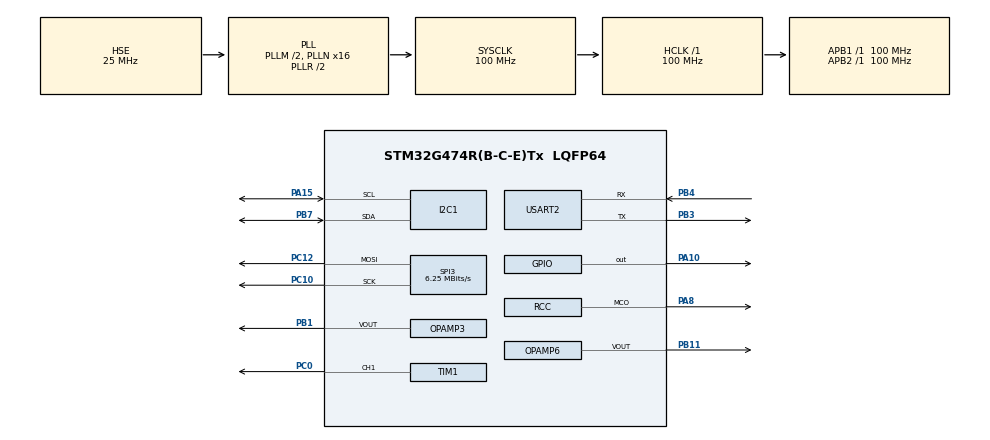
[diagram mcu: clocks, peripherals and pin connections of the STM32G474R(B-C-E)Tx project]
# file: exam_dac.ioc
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CRC.CRCLength=CRC_POLYLENGTH_16B
CRC.DefaultInitValueUse=DEFAULT_INIT_VALUE_DISABLE
CRC.DefaultPolynomialUse=DEFAULT_POLYNOMIAL_DISABLE
CRC.GeneratingPolynomial=X12+X5+X0
DAC3.DAC_Channel-DAC_OUT2_Int=DAC_CHANNEL_2
DAC3.DAC_DMADoubleDataMode-DAC_OUT1_Int=ENABLE
DAC3.DAC_DMADoubleDataMode-DAC_OUT2_Int=ENABLE
DAC3.DAC_Trigger_OUT1-DAC_OUT1_Int=DAC_TRIGGER_T15_TRGO
DAC3.DAC_Trigger_OUT2-DAC_OUT2_Int=DAC_TRIGGER_T15_TRGO
Dma.DAC3_CH1.1.Direction=DMA_MEMORY_TO_PERIPH
Dma.DAC3_CH1.1.EventEnable=DISABLE
Dma.DAC3_CH1.1.Instance=DMA1_Channel1
Dma.DAC3_CH1.1.MemDataAlignment=DMA_MDATAALIGN_WORD
Dma.DAC3_CH1.1.MemInc=DMA_MINC_ENABLE
Dma.DAC3_CH1.1.Mode=DMA_CIRCULAR
Dma.DAC3_CH1.1.PeriphDataAlignment=DMA_PDATAALIGN_WORD
Dma.DAC3_CH1.1.PeriphInc=DMA_PINC_DISABLE
Dma.DAC3_CH1.1.Polarity=HAL_DMAMUX_REQ_GEN_RISING
Dma.DAC3_CH1.1.Priority=DMA_PRIORITY_LOW
Dma.DAC3_CH1.1.RequestNumber=1
Dma.DAC3_CH1.1.SignalID=NONE
Dma.DAC3_CH1.1.SyncEnable=DISABLE
Dma.DAC3_CH1.1.SyncPolarity=HAL_DMAMUX_SYNC_NO_EVENT
Dma.DAC3_CH1.1.SyncRequestNumber=1
Dma.DAC3_CH1.1.SyncSignalID=NONE
Dma.DAC3_CH2.2.Direction=DMA_MEMORY_TO_PERIPH
Dma.DAC3_CH2.2.EventEnable=DISABLE
Dma.DAC3_CH2.2.Instance=DMA1_Channel2
Dma.DAC3_CH2.2.MemDataAlignment=DMA_MDATAALIGN_WORD
Dma.DAC3_CH2.2.MemInc=DMA_MINC_ENABLE
Dma.DAC3_CH2.2.Mode=DMA_CIRCULAR
Dma.DAC3_CH2.2.PeriphDataAlignment=DMA_PDATAALIGN_WORD
Dma.DAC3_CH2.2.PeriphInc=DMA_PINC_DISABLE
Dma.DAC3_CH2.2.Polarity=HAL_DMAMUX_REQ_GEN_RISING
Dma.DAC3_CH2.2.Priority=DMA_PRIORITY_LOW
Dma.DAC3_CH2.2.RequestNumber=1
Dma.DAC3_CH2.2.SignalID=NONE
Dma.DAC3_CH2.2.SyncEnable=DISABLE
Dma.DAC3_CH2.2.SyncPolarity=HAL_DMAMUX_SYNC_NO_EVENT
Dma.DAC3_CH2.2.SyncRequestNumber=1
Dma.DAC3_CH2.2.SyncSignalID=NONE
Dma.Request0=USART2_RX
Dma.Request1=DAC3_CH1
Dma.Request2=DAC3_CH2
Dma.USART2_RX.0.Direction=DMA_PERIPH_TO_MEMORY
Dma.USART2_RX.0.EventEnable=DISABLE
Dma.USART2_RX.0.Instance=DMA2_Channel8
Dma.USART2_RX.0.MemDataAlignment=DMA_MDATAALIGN_BYTE
Dma.USART2_RX.0.MemInc=DMA_MINC_ENABLE
Dma.USART2_RX.0.Mode=DMA_NORMAL
Dma.USART2_RX.0.PeriphDataAlignment=DMA_PDATAALIGN_BYTE
Dma.USART2_RX.0.PeriphInc=DMA_PINC_DISABLE
Dma.USART2_RX.0.Polarity=HAL_DMAMUX_REQ_GEN_RISING
Dma.USART2_RX.0.Priority=DMA_PRIORITY_LOW
Dma.USART2_RX.0.RequestNumber=1
Dma.USART2_RX.0.SignalID=NONE
Dma.USART2_RX.0.SyncEnable=DISABLE
Dma.USART2_RX.0.SyncPolarity=HAL_DMAMUX_SYNC_NO_EVENT
Dma.USART2_RX.0.SyncRequestNumber=1
Dma.USART2_RX.0.SyncSignalID=NONE
I2C1.Timing=0x20B182BE
Mcu.Family=STM32G4
Mcu.Name=STM32G474R(B-C-E)Tx
Mcu.Package=LQFP64
NVIC.DMA2_Channel8_IRQn=true\:0\:0\:false\:false\:true\:false\:true\:true
NVIC.PriorityGroup=NVIC_PRIORITYGROUP_4
NVIC.USART2_IRQn=true\:0\:0\:false\:false\:true\:true\:true\:true
OPAMP3.PowerMode=OPAMP_POWERMODE_HIGHSPEED
OPAMP6.PowerMode=OPAMP_POWERMODE_HIGHSPEED
PA10.GPIO_Speed=GPIO_SPEED_FREQ_VERY_HIGH
PA10.PinState=GPIO_PIN_SET
PA10.Signal=GPIO_Output
PA13.Mode=Serial_Wire
PA13.Signal=SYS_JTMS-SWDIO
PA14.Mode=Serial_Wire
PA14.Signal=SYS_JTCK-SWCLK
PA15.Mode=I2C
PA15.Signal=I2C1_SCL
PA8.GPIO_Speed=GPIO_SPEED_FREQ_MEDIUM
PA8.Mode=Clock-out
PA8.Signal=RCC_MCO
PB1.Mode=Follower-DAC_OUT2-INP
PB1.Signal=OPAMP3_VOUT
PB11.Mode=Follower-DAC_OUT2-INP
PB11.Signal=OPAMP6_VOUT
PB3.Mode=Asynchronous
PB3.Signal=USART2_TX
PB4.Mode=Asynchronous
PB4.Signal=USART2_RX
PB7.Mode=I2C
PB7.Signal=I2C1_SDA
PC0.Signal=S_TIM1_CH1
PC10.Mode=TX_Only_Simplex_Unidirect_Master
PC10.Signal=SPI3_SCK
PC12.Mode=TX_Only_Simplex_Unidirect_Master
PC12.Signal=SPI3_MOSI
PF0-OSC_IN.Mode=HSE-External-Oscillator
PF0-OSC_IN.Signal=RCC_OSC_IN
PF1-OSC_OUT.Mode=HSE-External-Oscillator
PF1-OSC_OUT.Signal=RCC_OSC_OUT
ProjectManager.HeapSize=0x200
ProjectManager.StackSize=0x400
ProjectManager.TargetToolchain=STM32CubeIDE
RCC.ADC12Freq_Value=100000000
RCC.ADC345Freq_Value=100000000
RCC.AHBFreq_Value=100000000
RCC.APB1Freq_Value=100000000
RCC.APB1TimFreq_Value=100000000
RCC.APB2Freq_Value=100000000
RCC.APB2TimFreq_Value=100000000
RCC.CortexFreq_Value=100000000
RCC.EXTERNAL_CLOCK_VALUE=12288000
RCC.HCLKFreq_Value=100000000
RCC.HSE_VALUE=25000000
RCC.HSI48_VALUE=48000000
RCC.HSI_VALUE=16000000
RCC.LSE_VALUE=32768
RCC.PLLM=RCC_PLLM_DIV2
RCC.PLLN=16
RCC.PLLSourceVirtual=RCC_PLLSOURCE_HSE
RCC.RCC_MCO1Source=RCC_MCO1SOURCE_HSE
RCC.SYSCLKFreq_VALUE=100000000
RCC.SYSCLKSource=RCC_SYSCLKSOURCE_PLLCLK
RCC.USART2CLockSelection=RCC_USART2CLKSOURCE_SYSCLK
RCC.USBFreq_Value=100000000
RCC.VCOOutputFreq_Value=200000000
SH.S_TIM1_CH1.0=TIM1_CH1,PWM Generation1 CH1
SPI3.BaudRatePrescaler=SPI_BAUDRATEPRESCALER_16
SPI3.CLKPolarity=SPI_POLARITY_HIGH
SPI3.CalculateBaudRate=6.25 MBits/s
SPI3.DataSize=SPI_DATASIZE_16BIT
SPI3.Direction=SPI_DIRECTION_2LINES
SPI3.Mode=SPI_MODE_MASTER
SPI3.VirtualType=VM_MASTER
TIM1.Channel-PWM\ Generation1\ CH1=TIM_CHANNEL_1
TIM1.PeriodNoDither=24
TIM15.AutoReloadPreload=TIM_AUTORELOAD_PRELOAD_DISABLE
TIM15.Dithering=Disable
TIM15.Integer_PeriodDither=4
TIM15.PeriodNoDither=4
TIM15.RepetitionCounter=0
TIM15.TIM_MasterOutputTrigger=TIM_TRGO_UPDATE
USART2.VirtualMode-Asynchronous=VM_ASYNC
VP_CORDIC_VS_CORDIC.Mode=CORDIC_Activate
VP_CRC_VS_CRC.Mode=CRC_Activate
VP_DAC3_VS_DACI1.Mode=DAC_OUT1_Int
VP_DAC3_VS_DACI2.Mode=DAC_OUT2_Int
VP_SYS_VS_DBSignals.Mode=DisableDeadBatterySignals
VP_TIM15_VS_ClockSourceINT.Mode=Internal
VP_TIM1_VS_ClockSourceINT.Mode=Internal
board=custom

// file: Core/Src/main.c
/* USER CODE BEGIN Header */
/**
  ******************************************************************************
  * @file           : main.c
  * @brief          : Main program body
  ******************************************************************************
  * @attention
  *
  * Copyright (c) 2024 STMicroelectronics.
  * All rights reserved.
  *
  * This software is licensed under terms that can be found in the LICENSE file
  * in the root directory of this software component.
  * If no LICENSE file comes with this software, it is provided AS-IS.
  *
  ******************************************************************************
  */
/* USER CODE END Header */
#include "main.h"

/* USER CODE BEGIN Includes */
#include "dds.h"
#include <math.h>
#include <stm32g4xx_hal_cordic.h>
/* USER CODE END Includes */

CORDIC_HandleTypeDef hcordic;

CRC_HandleTypeDef hcrc;

DAC_HandleTypeDef hdac3;
DMA_HandleTypeDef hdma_dac3_ch1;
DMA_HandleTypeDef hdma_dac3_ch2;

I2C_HandleTypeDef hi2c1;

OPAMP_HandleTypeDef hopamp3;
OPAMP_HandleTypeDef hopamp6;

SPI_HandleTypeDef hspi3;

TIM_HandleTypeDef htim1;
TIM_HandleTypeDef htim15;

UART_HandleTypeDef huart2;
DMA_HandleTypeDef hdma_usart2_rx;

/* USER CODE BEGIN PV */
uint16_t sin_data[10]={621,730,797,797,730,621,511,444,444,511};
/* USER CODE END PV */

void SystemClock_Config(void);
static void MX_GPIO_Init(void);
static void MX_DMA_Init(void);
static void MX_CRC_Init(void);
static void MX_USART2_UART_Init(void);
static void MX_TIM1_Init(void);
static void MX_I2C1_Init(void);
static void MX_SPI3_Init(void);
static void MX_DAC3_Init(void);
static void MX_TIM15_Init(void);
static void MX_CORDIC_Init(void);
static void MX_OPAMP6_Init(void);
static void MX_OPAMP3_Init(void);
/* USER CODE BEGIN PFP */

#define length 10
void set_dac(uint16_t offset)
{

//	  uint32_t temp1[length];
//	  uint32_t temp2[length];
//	  uint16_t hsdac_buffer[length];
//	  for (int i = 0; i < length; ++i)
//	  {
//		  temp1[i] = (1llu<<32) / length * i;
//	  }
//
//	  HAL_CORDIC_CalculateZO(&hcordic, temp1, temp2, length,10);
//	  for (int i= 0 ; i < length; ++i)
//	  {
//		  hsdac_buffer[i] = (temp2[i] + (1<< 31))>>21;
//		  hsdac_buffer[i] += offset;
//	  }
	  HAL_DAC_Start_DMA(&hdac3, DAC1_CHANNEL_1, sin_data, length / 2, DAC_ALIGN_12B_R);
	  //HAL_DAC_Start_DMA(&hdac3, DAC1_CHANNEL_2, sin_data, length / 2, DAC_ALIGN_12B_R);
//	  uint16_t dither[1000];
//	  int time_dither = 4;
//	  float e = 0;
//	  for (int i = 0 ; i < 1000 ; ++i)
//	  {
//
//		  e /= 2;
//		  if (e <1.14 )
//		  {
//
//			  dither[i] = 2;
//			  e +=2 ;
//		  }
//		  else
//		  {
//			  dither[i] = 1;
//			  e += 1;
//		  }
//	  }
//	  uint16_t dither[10] = {4,4,4,4,5,4,4,4,4,5};
//	  HAL_TIM_Base_Start_DMA(&htim15 ,dither , 1000 );
//	  (&htim15)->Instance->ARR = (uint32_t)(4);
//	  HAL_TIM_PWM_Start(&htim15, TIM_CHANNEL_1);
	  (&htim15)->Instance->ARR = (uint32_t)(4);
	  HAL_OPAMP_Start(&hopamp6);
	 // HAL_OPAMP_Start(&hopamp3);
	  HAL_TIM_Base_Start(&htim15);

}
/* USER CODE END PFP */

int main(void)
{

  /* MCU Configuration--------------------------------------------------------*/

  /* Reset of all peripherals, Initializes the Flash interface and the Systick. */
  HAL_Init();

  /* Configure the system clock */
  SystemClock_Config();

  /* Initialize all configured peripherals */
  MX_GPIO_Init();
  MX_DMA_Init();
  MX_CRC_Init();
  MX_USART2_UART_Init();
  MX_TIM1_Init();
  MX_I2C1_Init();
  MX_SPI3_Init();
  MX_DAC3_Init();
  MX_TIM15_Init();
  MX_CORDIC_Init();
  MX_OPAMP6_Init();
  MX_OPAMP3_Init();
  /* USER CODE BEGIN 2 */
  set_dac(1241);
  /* USER CODE END 2 */

  /* Infinite loop */
  while (1)
  {

  }
}

void SystemClock_Config(void)
{
  RCC_OscInitTypeDef RCC_OscInitStruct = {0};
  RCC_ClkInitTypeDef RCC_ClkInitStruct = {0};

  /** Configure the main internal regulator output voltage
  */
  HAL_PWREx_ControlVoltageScaling(PWR_REGULATOR_VOLTAGE_SCALE1);

  /** Initializes the RCC Oscillators according to the specified parameters
  * in the RCC_OscInitTypeDef structure.
  */
  RCC_OscInitStruct.OscillatorType = RCC_OSCILLATORTYPE_HSE;
  RCC_OscInitStruct.HSEState = RCC_HSE_ON;
  RCC_OscInitStruct.PLL.PLLState = RCC_PLL_ON;
  RCC_OscInitStruct.PLL.PLLSource = RCC_PLLSOURCE_HSE;
  RCC_OscInitStruct.PLL.PLLM = RCC_PLLM_DIV2;
  RCC_OscInitStruct.PLL.PLLN = 16;
  RCC_OscInitStruct.PLL.PLLP = RCC_PLLP_DIV2;
  RCC_OscInitStruct.PLL.PLLQ = RCC_PLLQ_DIV2;
  RCC_OscInitStruct.PLL.PLLR = RCC_PLLR_DIV2;
  if (HAL_RCC_OscConfig(&RCC_OscInitStruct) != HAL_OK)
  {
    Error_Handler();
  }

  /** Initializes the CPU, AHB and APB buses clocks
  */
  RCC_ClkInitStruct.ClockType = RCC_CLOCKTYPE_HCLK|RCC_CLOCKTYPE_SYSCLK
                              |RCC_CLOCKTYPE_PCLK1|RCC_CLOCKTYPE_PCLK2;
  RCC_ClkInitStruct.SYSCLKSource = RCC_SYSCLKSOURCE_PLLCLK;
  RCC_ClkInitStruct.AHBCLKDivider = RCC_SYSCLK_DIV1;
  RCC_ClkInitStruct.APB1CLKDivider = RCC_HCLK_DIV1;
  RCC_ClkInitStruct.APB2CLKDivider = RCC_HCLK_DIV1;

  if (HAL_RCC_ClockConfig(&RCC_ClkInitStruct, FLASH_LATENCY_3) != HAL_OK)
  {
    Error_Handler();
  }
  HAL_RCC_MCOConfig(RCC_MCO1, RCC_MCO1SOURCE_HSE, RCC_MCODIV_1);
}

static void MX_CORDIC_Init(void)
{

  hcordic.Instance = CORDIC;
  if (HAL_CORDIC_Init(&hcordic) != HAL_OK)
  {
    Error_Handler();
  }

}

static void MX_CRC_Init(void)
{

  hcrc.Instance = CRC;
  hcrc.Init.DefaultPolynomialUse = DEFAULT_POLYNOMIAL_DISABLE;
  hcrc.Init.DefaultInitValueUse = DEFAULT_INIT_VALUE_DISABLE;
  hcrc.Init.GeneratingPolynomial = 4129;
  hcrc.Init.CRCLength = CRC_POLYLENGTH_16B;
  hcrc.Init.InitValue = 0;
  hcrc.Init.InputDataInversionMode = CRC_INPUTDATA_INVERSION_NONE;
  hcrc.Init.OutputDataInversionMode = CRC_OUTPUTDATA_INVERSION_DISABLE;
  hcrc.InputDataFormat = CRC_INPUTDATA_FORMAT_BYTES;
  if (HAL_CRC_Init(&hcrc) != HAL_OK)
  {
    Error_Handler();
  }

}

static void MX_DAC3_Init(void)
{

  DAC_ChannelConfTypeDef sConfig = {0};

  /** DAC Initialization
  */
  hdac3.Instance = DAC3;
  if (HAL_DAC_Init(&hdac3) != HAL_OK)
  {
    Error_Handler();
  }

  /** DAC channel OUT1 config
  */
  sConfig.DAC_HighFrequency = DAC_HIGH_FREQUENCY_INTERFACE_MODE_AUTOMATIC;
  sConfig.DAC_DMADoubleDataMode = ENABLE;
  sConfig.DAC_SignedFormat = DISABLE;
  sConfig.DAC_SampleAndHold = DAC_SAMPLEANDHOLD_DISABLE;
  sConfig.DAC_Trigger = DAC_TRIGGER_T15_TRGO;
  sConfig.DAC_Trigger2 = DAC_TRIGGER_NONE;
  sConfig.DAC_OutputBuffer = DAC_OUTPUTBUFFER_DISABLE;
  sConfig.DAC_ConnectOnChipPeripheral = DAC_CHIPCONNECT_INTERNAL;
  sConfig.DAC_UserTrimming = DAC_TRIMMING_FACTORY;
  if (HAL_DAC_ConfigChannel(&hdac3, &sConfig, DAC_CHANNEL_1) != HAL_OK)
  {
    Error_Handler();
  }

  /** DAC channel OUT2 config
  */
  if (HAL_DAC_ConfigChannel(&hdac3, &sConfig, DAC_CHANNEL_2) != HAL_OK)
  {
    Error_Handler();
  }

}

static void MX_I2C1_Init(void)
{

  hi2c1.Instance = I2C1;
  hi2c1.Init.Timing = 0x20B182BE;
  hi2c1.Init.OwnAddress1 = 0;
  hi2c1.Init.AddressingMode = I2C_ADDRESSINGMODE_7BIT;
  hi2c1.Init.DualAddressMode = I2C_DUALADDRESS_DISABLE;
  hi2c1.Init.OwnAddress2 = 0;
  hi2c1.Init.OwnAddress2Masks = I2C_OA2_NOMASK;
  hi2c1.Init.GeneralCallMode = I2C_GENERALCALL_DISABLE;
  hi2c1.Init.NoStretchMode = I2C_NOSTRETCH_DISABLE;
  if (HAL_I2C_Init(&hi2c1) != HAL_OK)
  {
    Error_Handler();
  }

  /** Configure Analogue filter
  */
  if (HAL_I2CEx_ConfigAnalogFilter(&hi2c1, I2C_ANALOGFILTER_ENABLE) != HAL_OK)
  {
    Error_Handler();
  }

  /** Configure Digital filter
  */
  if (HAL_I2CEx_ConfigDigitalFilter(&hi2c1, 0) != HAL_OK)
  {
    Error_Handler();
  }

}

static void MX_OPAMP3_Init(void)
{

  hopamp3.Instance = OPAMP3;
  hopamp3.Init.PowerMode = OPAMP_POWERMODE_HIGHSPEED;
  hopamp3.Init.Mode = OPAMP_FOLLOWER_MODE;
  hopamp3.Init.NonInvertingInput = OPAMP_NONINVERTINGINPUT_DAC;
  hopamp3.Init.InternalOutput = DISABLE;
  hopamp3.Init.TimerControlledMuxmode = OPAMP_TIMERCONTROLLEDMUXMODE_DISABLE;
  hopamp3.Init.UserTrimming = OPAMP_TRIMMING_FACTORY;
  if (HAL_OPAMP_Init(&hopamp3) != HAL_OK)
  {
    Error_Handler();
  }

}

static void MX_OPAMP6_Init(void)
{

  hopamp6.Instance = OPAMP6;
  hopamp6.Init.PowerMode = OPAMP_POWERMODE_HIGHSPEED;
  hopamp6.Init.Mode = OPAMP_FOLLOWER_MODE;
  hopamp6.Init.NonInvertingInput = OPAMP_NONINVERTINGINPUT_DAC;
  hopamp6.Init.InternalOutput = DISABLE;
  hopamp6.Init.TimerControlledMuxmode = OPAMP_TIMERCONTROLLEDMUXMODE_DISABLE;
  hopamp6.Init.UserTrimming = OPAMP_TRIMMING_FACTORY;
  if (HAL_OPAMP_Init(&hopamp6) != HAL_OK)
  {
    Error_Handler();
  }

}

static void MX_SPI3_Init(void)
{

  /* SPI3 parameter configuration*/
  hspi3.Instance = SPI3;
  hspi3.Init.Mode = SPI_MODE_MASTER;
  hspi3.Init.Direction = SPI_DIRECTION_2LINES;
  hspi3.Init.DataSize = SPI_DATASIZE_16BIT;
  hspi3.Init.CLKPolarity = SPI_POLARITY_HIGH;
  hspi3.Init.CLKPhase = SPI_PHASE_1EDGE;
  hspi3.Init.NSS = SPI_NSS_SOFT;
  hspi3.Init.BaudRatePrescaler = SPI_BAUDRATEPRESCALER_16;
  hspi3.Init.FirstBit = SPI_FIRSTBIT_MSB;
  hspi3.Init.TIMode = SPI_TIMODE_DISABLE;
  hspi3.Init.CRCCalculation = SPI_CRCCALCULATION_DISABLE;
  hspi3.Init.CRCPolynomial = 7;
  hspi3.Init.CRCLength = SPI_CRC_LENGTH_DATASIZE;
  hspi3.Init.NSSPMode = SPI_NSS_PULSE_ENABLE;
  if (HAL_SPI_Init(&hspi3) != HAL_OK)
  {
    Error_Handler();
  }

}

static void MX_TIM1_Init(void)
{

  TIM_ClockConfigTypeDef sClockSourceConfig = {0};
  TIM_MasterConfigTypeDef sMasterConfig = {0};
  TIM_OC_InitTypeDef sConfigOC = {0};
  TIM_BreakDeadTimeConfigTypeDef sBreakDeadTimeConfig = {0};

  htim1.Instance = TIM1;
  htim1.Init.Prescaler = 0;
  htim1.Init.CounterMode = TIM_COUNTERMODE_UP;
  htim1.Init.Period = 24;
  htim1.Init.ClockDivision = TIM_CLOCKDIVISION_DIV1;
  htim1.Init.RepetitionCounter = 0;
  htim1.Init.AutoReloadPreload = TIM_AUTORELOAD_PRELOAD_DISABLE;
  if (HAL_TIM_Base_Init(&htim1) != HAL_OK)
  {
    Error_Handler();
  }
  sClockSourceConfig.ClockSource = TIM_CLOCKSOURCE_INTERNAL;
  if (HAL_TIM_ConfigClockSource(&htim1, &sClockSourceConfig) != HAL_OK)
  {
    Error_Handler();
  }
  if (HAL_TIM_PWM_Init(&htim1) != HAL_OK)
  {
    Error_Handler();
  }
  sMasterConfig.MasterOutputTrigger = TIM_TRGO_RESET;
  sMasterConfig.MasterOutputTrigger2 = TIM_TRGO2_RESET;
  sMasterConfig.MasterSlaveMode = TIM_MASTERSLAVEMODE_DISABLE;
  if (HAL_TIMEx_MasterConfigSynchronization(&htim1, &sMasterConfig) != HAL_OK)
  {
    Error_Handler();
  }
  sConfigOC.OCMode = TIM_OCMODE_PWM1;
  sConfigOC.Pulse = 0;
  sConfigOC.OCPolarity = TIM_OCPOLARITY_HIGH;
  sConfigOC.OCNPolarity = TIM_OCNPOLARITY_HIGH;
  sConfigOC.OCFastMode = TIM_OCFAST_DISABLE;
  sConfigOC.OCIdleState = TIM_OCIDLESTATE_RESET;
  sConfigOC.OCNIdleState = TIM_OCNIDLESTATE_RESET;
  if (HAL_TIM_PWM_ConfigChannel(&htim1, &sConfigOC, TIM_CHANNEL_1) != HAL_OK)
  {
    Error_Handler();
  }
  sBreakDeadTimeConfig.OffStateRunMode = TIM_OSSR_DISABLE;
  sBreakDeadTimeConfig.OffStateIDLEMode = TIM_OSSI_DISABLE;
  sBreakDeadTimeConfig.LockLevel = TIM_LOCKLEVEL_OFF;
  sBreakDeadTimeConfig.DeadTime = 0;
  sBreakDeadTimeConfig.BreakState = TIM_BREAK_DISABLE;
  sBreakDeadTimeConfig.BreakPolarity = TIM_BREAKPOLARITY_HIGH;
  sBreakDeadTimeConfig.BreakFilter = 0;
  sBreakDeadTimeConfig.BreakAFMode = TIM_BREAK_AFMODE_INPUT;
  sBreakDeadTimeConfig.Break2State = TIM_BREAK2_DISABLE;
  sBreakDeadTimeConfig.Break2Polarity = TIM_BREAK2POLARITY_HIGH;
  sBreakDeadTimeConfig.Break2Filter = 0;
  sBreakDeadTimeConfig.Break2AFMode = TIM_BREAK_AFMODE_INPUT;
  sBreakDeadTimeConfig.AutomaticOutput = TIM_AUTOMATICOUTPUT_DISABLE;
  if (HAL_TIMEx_ConfigBreakDeadTime(&htim1, &sBreakDeadTimeConfig) != HAL_OK)
  {
    Error_Handler();
  }
  HAL_TIM_MspPostInit(&htim1);

}

static void MX_TIM15_Init(void)
{

  TIM_ClockConfigTypeDef sClockSourceConfig = {0};
  TIM_MasterConfigTypeDef sMasterConfig = {0};

  htim15.Instance = TIM15;
  htim15.Init.Prescaler = 0;
  htim15.Init.CounterMode = TIM_COUNTERMODE_UP;
  htim15.Init.Period = 4;
  htim15.Init.ClockDivision = TIM_CLOCKDIVISION_DIV1;
  htim15.Init.RepetitionCounter = 0;
  htim15.Init.AutoReloadPreload = TIM_AUTORELOAD_PRELOAD_DISABLE;
  if (HAL_TIM_Base_Init(&htim15) != HAL_OK)
  {
    Error_Handler();
  }
  sClockSourceConfig.ClockSource = TIM_CLOCKSOURCE_INTERNAL;
  if (HAL_TIM_ConfigClockSource(&htim15, &sClockSourceConfig) != HAL_OK)
  {
    Error_Handler();
  }
  sMasterConfig.MasterOutputTrigger = TIM_TRGO_UPDATE;
  sMasterConfig.MasterSlaveMode = TIM_MASTERSLAVEMODE_DISABLE;
  if (HAL_TIMEx_MasterConfigSynchronization(&htim15, &sMasterConfig) != HAL_OK)
  {
    Error_Handler();
  }

}

static void MX_USART2_UART_Init(void)
{

  huart2.Instance = USART2;
  huart2.Init.BaudRate = 115200;
  huart2.Init.WordLength = UART_WORDLENGTH_8B;
  huart2.Init.StopBits = UART_STOPBITS_1;
  huart2.Init.Parity = UART_PARITY_NONE;
  huart2.Init.Mode = UART_MODE_TX_RX;
  huart2.Init.HwFlowCtl = UART_HWCONTROL_NONE;
  huart2.Init.OverSampling = UART_OVERSAMPLING_16;
  huart2.Init.OneBitSampling = UART_ONE_BIT_SAMPLE_DISABLE;
  huart2.Init.ClockPrescaler = UART_PRESCALER_DIV1;
  huart2.AdvancedInit.AdvFeatureInit = UART_ADVFEATURE_NO_INIT;
  if (HAL_UART_Init(&huart2) != HAL_OK)
  {
    Error_Handler();
  }
  if (HAL_UARTEx_SetTxFifoThreshold(&huart2, UART_TXFIFO_THRESHOLD_1_8) != HAL_OK)
  {
    Error_Handler();
  }
  if (HAL_UARTEx_SetRxFifoThreshold(&huart2, UART_RXFIFO_THRESHOLD_1_8) != HAL_OK)
  {
    Error_Handler();
  }
  if (HAL_UARTEx_DisableFifoMode(&huart2) != HAL_OK)
  {
    Error_Handler();
  }

}

static void MX_DMA_Init(void)
{

  /* DMA controller clock enable */
  __HAL_RCC_DMAMUX1_CLK_ENABLE();
  __HAL_RCC_DMA2_CLK_ENABLE();
  __HAL_RCC_DMA1_CLK_ENABLE();

  /* DMA interrupt init */
  /* DMA2_Channel8_IRQn interrupt configuration */
  HAL_NVIC_SetPriority(DMA2_Channel8_IRQn, 0, 0);
  HAL_NVIC_EnableIRQ(DMA2_Channel8_IRQn);

}

static void MX_GPIO_Init(void)
{
  GPIO_InitTypeDef GPIO_InitStruct = {0};

  /* GPIO Ports Clock Enable */
  __HAL_RCC_GPIOF_CLK_ENABLE();
  __HAL_RCC_GPIOC_CLK_ENABLE();
  __HAL_RCC_GPIOB_CLK_ENABLE();
  __HAL_RCC_GPIOA_CLK_ENABLE();

  /*Configure GPIO pin Output Level */
  HAL_GPIO_WritePin(GPIOA, GPIO_PIN_10, GPIO_PIN_SET);

  /*Configure GPIO pin : PA8 */
  GPIO_InitStruct.Pin = GPIO_PIN_8;
  GPIO_InitStruct.Mode = GPIO_MODE_AF_PP;
  GPIO_InitStruct.Pull = GPIO_NOPULL;
  GPIO_InitStruct.Speed = GPIO_SPEED_FREQ_MEDIUM;
  GPIO_InitStruct.Alternate = GPIO_AF0_MCO;
  HAL_GPIO_Init(GPIOA, &GPIO_InitStruct);

  /*Configure GPIO pin : PA10 */
  GPIO_InitStruct.Pin = GPIO_PIN_10;
  GPIO_InitStruct.Mode = GPIO_MODE_OUTPUT_PP;
  GPIO_InitStruct.Pull = GPIO_NOPULL;
  GPIO_InitStruct.Speed = GPIO_SPEED_FREQ_VERY_HIGH;
  HAL_GPIO_Init(GPIOA, &GPIO_InitStruct);

}

void Error_Handler(void)
{
  __disable_irq();
  while (1)
  {
  }
}
